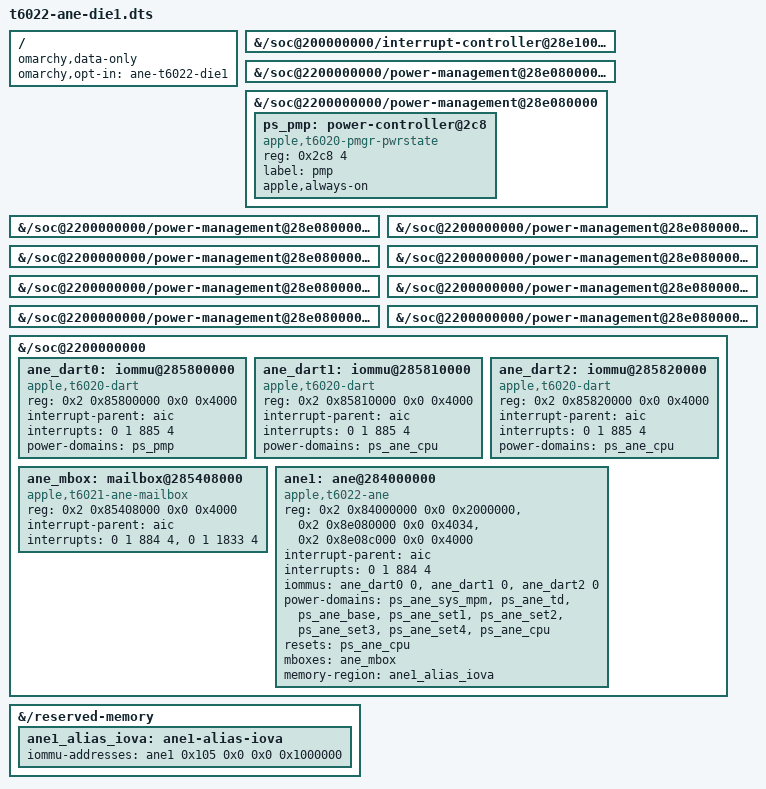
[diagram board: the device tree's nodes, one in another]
// SPDX-License-Identifier: GPL-2.0+ OR MIT
/*
 * The die-1 ANE of T6022 (M2 Ultra): data-only until M4
 * (docs/ultra-die1.md §8). omarchy,data-only keeps it out of every
 * installed overlay set (build-dtbo compiles it as a check, it is never
 * installed, omarchy-ane-dt apply never applies it): ane_t6021 has no
 * qualification gate, so an enabled die-1 node would bind and boot
 * unproven die-1 firmware. M4 flips this overlay to opt-in
 * ("ane-t6022-die1") once a die-1 run proves the boot; the opt-in key
 * is already named here.
 *
 * Shapes and values: receipts/2026-10-03-ultra-die1 (13.5 ADT j475d
 * decode; die 1 is the pure +0x20_0000_0000 translation of die 0 for
 * every window) and the aurora t602x.dtsi multi-die template. Node
 * names and regs stay in the die-1 bus's untranslated (child) address
 * space; the bus ranges (t6022.dtsi: soc@2200000000, 0x2_x -> 0x22_x)
 * translate them (engine 0x284000000 -> 0x2284000000, SET window
 * 0x28e08c000 -> 0x228e08c000, whose die-1 pmu_pa the ane_t6021 module
 * already carries: ane_t6022_soc_die1).
 *
 * Interrupts keep the die-0 line numbers with the die in the AIC
 * specifier (884 ane and mailbox recv, 885 DART): the aurora AIC_IRQ
 * DIE_NO column routes by die. INFERENCE, marked where not measured:
 * the die-1 mailbox send-empty line (1833, an unused AIC2 line the
 * stock TX only waits on while the A2I FIFO is full — ane_t6021 leaves
 * the mailbox stopped) and the die-1 ane-alias IOVA (the die-0 vm-base
 * +0x20_0000_0000; the die-1 DART vm-base is a missing fact, §9.5).
 * The die-1 pmgr states all exist on the stock trees (aurora/upstream
 * DIE_NODE(ps_ane_sys), ps_ane_cpu, ps_ane_sys_mpm, ps_ane_td,
 * ps_ane_base, ps_ane_set1..4, both dies): the fragments only label
 * them. The die-1 mailbox, DARTs and ane node do not exist anywhere:
 * this overlay adds them, per the die-0 t602x-ane.dtsi shape.
 */
/dts-v1/;
/plugin/;

/ {
	/* Never applied while data-only; M4 makes this the opt-in key. */
	omarchy,data-only;
	omarchy,opt-in = "ane-t6022-die1";
};

/ {
	fragment@0 {
		target-path = "/soc@200000000/interrupt-controller@28e100000";
		aic: __overlay__ {
		};
	};

	fragment@1 {
		target-path = "/soc@2200000000/power-management@28e080000/power-controller@260";
		ps_ane_sys: __overlay__ {
		};
	};

	fragment@2 {
		target-path = "/soc@2200000000/power-management@28e080000";

		__overlay__ {
			/* The stock trees disagree: aurora compiles the die-1
			 * pmp (t602x-pmgr.dtsi DIE_NODE(ps_pmp), "PMP is only
			 * present on die 0" notwithstanding), linux-asahi
			 * 7.1.13 ships none. The die-1 DART sits in the pmp
			 * domain as die 0 does, so this fragment defines the
			 * node where a tree lacks it and merges the same
			 * properties where it has one. */
			ps_pmp: power-controller@2c8 {
				compatible = "apple,t6020-pmgr-pwrstate", "apple,t8103-pmgr-pwrstate", "apple,pmgr-pwrstate";
				reg = <0x2c8 4>;
				#power-domain-cells = <0>;
				#reset-cells = <0>;
				label = "pmp";
				apple,always-on;
			};
		};
	};

	fragment@3 {
		target-path = "/soc@2200000000/power-management@28e080000/power-controller@2e0";
		ps_ane_cpu: __overlay__ {
		};
	};

	fragment@4 {
		target-path = "/soc@2200000000/power-management@28e080000/power-controller@4000";
		ps_ane_sys_mpm: __overlay__ {
		};
	};

	fragment@5 {
		target-path = "/soc@2200000000/power-management@28e080000/power-controller@4008";
		ps_ane_td: __overlay__ {
		};
	};

	fragment@6 {
		target-path = "/soc@2200000000/power-management@28e080000/power-controller@4010";
		ps_ane_base: __overlay__ {
		};
	};

	fragment@7 {
		target-path = "/soc@2200000000/power-management@28e080000/power-controller@4018";
		ps_ane_set1: __overlay__ {
		};
	};

	fragment@8 {
		target-path = "/soc@2200000000/power-management@28e080000/power-controller@4020";
		ps_ane_set2: __overlay__ {
		};
	};

	fragment@9 {
		target-path = "/soc@2200000000/power-management@28e080000/power-controller@4028";
		ps_ane_set3: __overlay__ {
		};
	};

	fragment@10 {
		target-path = "/soc@2200000000/power-management@28e080000/power-controller@4030";
		ps_ane_set4: __overlay__ {
		};
	};

	fragment@11 {
		target-path = "/soc@2200000000";

		__overlay__ {
			ane_dart0: iommu@285800000 {
				compatible = "apple,t6020-dart", "apple,t8110-dart";
				reg = <0x2 0x85800000 0x0 0x4000>;
				#iommu-cells = <1>;
				interrupt-parent = <&aic>;
				interrupts = <0 1 885 4>;
				power-domains = <&ps_pmp>;
				status = "okay";
			};

			ane_dart1: iommu@285810000 {
				compatible = "apple,t6020-dart", "apple,t8110-dart";
				reg = <0x2 0x85810000 0x0 0x4000>;
				#iommu-cells = <1>;
				interrupt-parent = <&aic>;
				interrupts = <0 1 885 4>;
				power-domains = <&ps_ane_cpu>;
				status = "okay";
			};

			ane_dart2: iommu@285820000 {
				compatible = "apple,t6020-dart", "apple,t8110-dart";
				reg = <0x2 0x85820000 0x0 0x4000>;
				#iommu-cells = <1>;
				interrupt-parent = <&aic>;
				interrupts = <0 1 885 4>;
				power-domains = <&ps_ane_cpu>;
				status = "okay";
			};

			ane_mbox: mailbox@285408000 {
				compatible = "apple,t6021-ane-mailbox", "apple,asc-mailbox-v4";
				reg = <0x2 0x85408000 0x0 0x4000>;
				interrupt-parent = <&aic>;
				interrupt-names = "recv-not-empty", "send-empty";
				interrupts = <0 1 884 4>, <0 1 1833 4>;
				#mbox-cells = <0>;
				status = "okay";
			};

			ane1: ane@284000000 {
				compatible = "apple,t6022-ane";
				reg-names = "engine", "pmgr", "set";
				reg = <0x2 0x84000000 0x0 0x2000000>,
				      <0x2 0x8e080000 0x0 0x4034>,
				      <0x2 0x8e08c000 0x0 0x4000>;
				interrupt-parent = <&aic>;
				interrupt-names = "ane";
				interrupts = <0 1 884 4>;
				iommus = <&ane_dart0 0>, <&ane_dart1 0>, <&ane_dart2 0>;
				power-domains = <&ps_ane_sys_mpm>, <&ps_ane_td>, <&ps_ane_base>,
						<&ps_ane_set1>, <&ps_ane_set2>, <&ps_ane_set3>,
						<&ps_ane_set4>, <&ps_ane_cpu>;
				resets = <&ps_ane_cpu>;
				mboxes = <&ane_mbox>;
				memory-region = <&ane1_alias_iova>;
				status = "okay";
			};
		};
	};

	fragment@12 {
		target-path = "/reserved-memory";

		__overlay__ {
			/* INFERENCE: die-0 vm-base +0x20_0000_0000 (the die-1
			 * DART vm-base is a missing fact, docs/ultra-die1.md §9.5). */
			ane1_alias_iova: ane1-alias-iova {
				iommu-addresses = <&ane1 0x105 0x0 0x0 0x1000000>;
			};
		};
	};
};
